AUTOSAR XML (schema 4.0)
standard types defined: float32, float64, sint16, sint32, sint8, uint16, uint32, uint8, void, boolean
package /ImplDataTypes
  impl type MultiStateBtnType: implementation-data-type=uint8, type-emitter=RTE
  impl type StepMotorStepType: implementation-data-type=uint8, type-emitter=RTE
package /MappingSets
  data type mapping set MappingSet
package /PortInterfaces/ClientServer
  client server interface CsIf_StepMotor
    operation Opr_Move
      arg step: type=StepMotorStepType, direction=IN
package /PortInterfaces/SenderReceiver
  sender receiver interface SrIf_SeatCtrlBtns
    data HeightBtnState: type=MultiStateBtnType
    data IncineBtnState: type=MultiStateBtnType
    data SlideBtnState: type=MultiStateBtnType
  sender receiver interface SrIf_SeatCtrlData
    data Height: type=uint8
    data Incline: type=uint8
    data Slide: type=uint8
package /SoftwareComponents
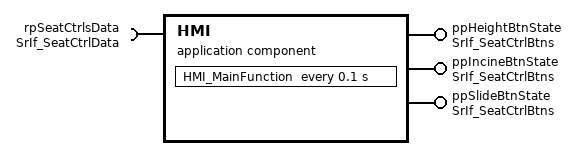
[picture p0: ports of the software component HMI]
  application sw component type HMI
    provide port ppHeightBtnState: provided-interface=SrIf_SeatCtrlBtns
    provide port ppIncineBtnState: provided-interface=SrIf_SeatCtrlBtns
    provide port ppSlideBtnState: provided-interface=SrIf_SeatCtrlBtns
    require port rpSeatCtrlsData: required-interface=SrIf_SeatCtrlData
    behavior Ibhv_HMI: data-type-mapping=MappingSet, handle-termination-and-restart=NO-SUPPORT
      timing event TE_HMI_MainFunction_100ms: start-on-event=HMI_MainFunction, period=0.1
      runnable HMI_MainFunction
        data-receive-point-by-arguments:
          access DRP_rpSeatCtrlsData_Height: accessed-variable=rpSeatCtrlsData.Height
          access DRP_rpSeatCtrlsData_Incline: accessed-variable=rpSeatCtrlsData.Incline
          access DRP_rpSeatCtrlsData_Slide: accessed-variable=rpSeatCtrlsData.Slide
        data-send-points:
          access DSP_ppHeightBtnState_HeightBtnState: accessed-variable=ppHeightBtnState.HeightBtnState
          access DSP_ppIncineBtnState_IncineBtnState: accessed-variable=ppIncineBtnState.IncineBtnState
          access DSP_ppSlideBtnState_SlideBtnState: accessed-variable=ppSlideBtnState.SlideBtnState
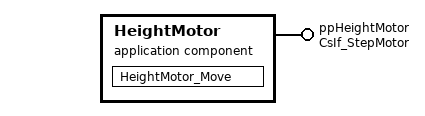
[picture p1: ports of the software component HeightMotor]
  application sw component type HeightMotor
    provide port ppHeightMotor: provided-interface=CsIf_StepMotor
    behavior Ibhv_HeightMotor: data-type-mapping=MappingSet, handle-termination-and-restart=NO-SUPPORT
      operation invoked event OIE_ppHeightMotor_Opr_Move: start-on-event=HeightMotor_Move, operation=ppHeightMotor.Opr_Move
      runnable HeightMotor_Move
  5 x swc implementation, all with programming-language=C, sw-version=1.0.0, vendor-id=255:
    Impl_HMI: behavior=Ibhv_HMI
      code-descriptors:
        code Code: artifact-descriptors=autosar-engineering-object={short-label=SWC.c, category=SWSRC}
      resource consumption ResourceConsumption
    Impl_HeightMotor: behavior=Ibhv_HeightMotor
      code-descriptors:
        code Code: artifact-descriptors=autosar-engineering-object={short-label=SWC.c, category=SWSRC}
      resource consumption ResourceConsumption
    Impl_InclineMotor: behavior=Ibhv_InclineMotor
      code-descriptors:
        code Code: artifact-descriptors=autosar-engineering-object={short-label=SWC.c, category=SWSRC}
      resource consumption ResourceConsumption
    Impl_SeatManager: behavior=Ibhv_SeatManager
      code-descriptors:
        code Code: artifact-descriptors=autosar-engineering-object={short-label=SWC.c, category=SWSRC}
      resource consumption ResourceConsumption
    Impl_SlideMotor: behavior=Ibhv_SlideMotor
      code-descriptors:
        code Code: artifact-descriptors=autosar-engineering-object={short-label=SWC.c, category=SWSRC}
      resource consumption ResourceConsumption
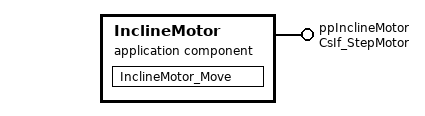
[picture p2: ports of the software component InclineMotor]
  application sw component type InclineMotor
    provide port ppInclineMotor: provided-interface=CsIf_StepMotor
    behavior Ibhv_InclineMotor: data-type-mapping=MappingSet, handle-termination-and-restart=NO-SUPPORT
      operation invoked event OIE_ppInclineMotor_Opr_Move: start-on-event=InclineMotor_Move, operation=ppInclineMotor.Opr_Move
      runnable InclineMotor_Move
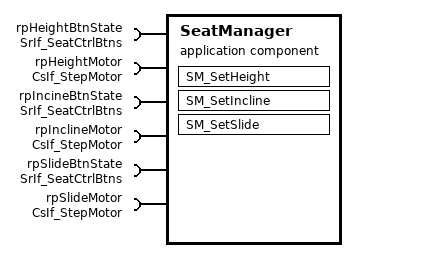
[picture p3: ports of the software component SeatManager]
  application sw component type SeatManager
    6 x require port:
      rpHeightBtnState: required-interface=SrIf_SeatCtrlBtns
      rpHeightMotor: required-interface=CsIf_StepMotor
      rpIncineBtnState: required-interface=SrIf_SeatCtrlBtns
      rpInclineMotor: required-interface=CsIf_StepMotor
      rpSlideBtnState: required-interface=SrIf_SeatCtrlBtns
      rpSlideMotor: required-interface=CsIf_StepMotor
    behavior Ibhv_SeatManager: data-type-mapping=MappingSet, handle-termination-and-restart=NO-SUPPORT
      data received event DRE__: start-on-event=SM_SetIncline, data=rpSeatCtrlBtns.InclineBtnState
      data received event DRE__HeightBtnState: start-on-event=SM_SetHeight, data=rpSeatCtrlBtns.HeightBtnState
      data received event DRE__SlideBtnState: start-on-event=SM_SetSlide, data=rpSeatCtrlBtns.SlideBtnState
      runnable SM_SetHeight
        data-receive-point-by-arguments:
          access DRP_rpHeightBtnState_HeightBtnState: accessed-variable=rpHeightBtnState.HeightBtnState
        sync call SCP_rpHeightMotor_Opr_Move: operation=rpHeightMotor.Opr_Move, timeout=0.0
      runnable SM_SetIncline
        data-receive-point-by-arguments:
          access DRP_rpIncineBtnState_IncineBtnState: accessed-variable=rpIncineBtnState.IncineBtnState
        sync call SCP_rpInclineMotor_Opr_Move: operation=rpInclineMotor.Opr_Move, timeout=0.0
      runnable SM_SetSlide
        data-receive-point-by-arguments:
          access DRP_rpSlideBtnState_SlideBtnState: accessed-variable=rpSlideBtnState.SlideBtnState
        sync call SCP_rpSlideMotor_Opr_Move: operation=rpSlideMotor.Opr_Move, timeout=0.0
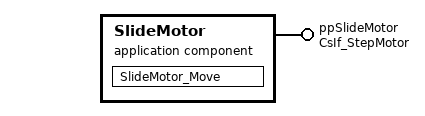
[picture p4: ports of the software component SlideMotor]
  application sw component type SlideMotor
    provide port ppSlideMotor: provided-interface=CsIf_StepMotor
    behavior Ibhv_SlideMotor: data-type-mapping=MappingSet, handle-termination-and-restart=NO-SUPPORT
      operation invoked event OIE_ppSlideMotor_Opr_Move: start-on-event=SlideMotor_Move, operation=ppSlideMotor.Opr_Move
      runnable SlideMotor_Move
package /Compositions
  composition sw component type Task3Composition
    5 x component:
      HMI: type=HMI
      HeightMotor: type=HeightMotor
      InclineMotor: type=InclineMotor
      SeatManager: type=SeatManager
      SlideMotor: type=SlideMotor
    connect HMI.ppHeightBtnState -> SeatManager.rpHeightBtnState
    connect HMI.ppIncineBtnState -> SeatManager.rpIncineBtnState
    connect HMI.ppSlideBtnState -> SeatManager.rpSlideBtnState
    connect HeightMotor.ppHeightMotor -> SeatManager.rpHeightMotor
    connect InclineMotor.ppInclineMotor -> SeatManager.rpInclineMotor
    connect SlideMotor.ppSlideMotor -> SeatManager.rpSlideMotor
